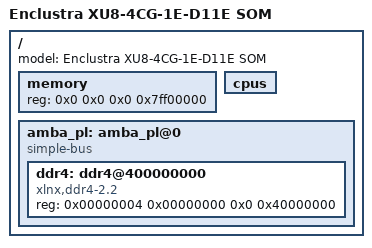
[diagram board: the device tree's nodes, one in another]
#include "zynqmp.dtsi"
#include "zynqmp-clk-ccf.dtsi"
#include "zynqmp_enclustra_common.dtsi"
#include "zynqmp_enclustra_mercury_xu8.dtsi"

/ {
	model = "Enclustra XU8-4CG-1E-D11E SOM";

	memory {
		device_type = "memory";
		reg = <0x0 0x0 0x0 0x7ff00000>;
	};

	cpus {
		/delete-node/ cpu@2 ;
		/delete-node/ cpu@3 ;
	};

/******************** PL entries **********************/

	amba_pl: amba_pl@0 {
		#address-cells = <2>;
		#size-cells = <2>;
		compatible = "simple-bus";
		ranges ;
		ddr4: ddr4@400000000 {
			compatible = "xlnx,ddr4-2.2";
			reg = <0x00000004 0x00000000 0x0 0x40000000>;
		};
	};
	
/******************** PL entries **********************/

};
